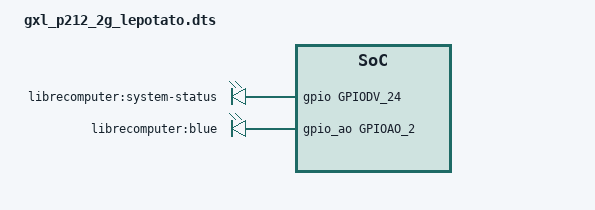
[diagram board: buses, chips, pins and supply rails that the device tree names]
#include "gxl_p212_2g.dts"

/ {
	le-dt-id = "gxl_p212_2g_lepotato";
	leds: gpio_leds {
		compatible = "gpio-leds";

		system {
			label = "librecomputer:system-status";
			gpios = <&gpio GPIODV_24 GPIO_ACTIVE_HIGH>;
			default-state = "on";
			panic-indicator;
		};

		blue {
			label = "librecomputer:blue";
			gpios = <&gpio_ao GPIOAO_2 GPIO_ACTIVE_HIGH>;
			default-state = "on";
		};
	};

	gpio_keypad {
		status = "disabled";
	};

};
